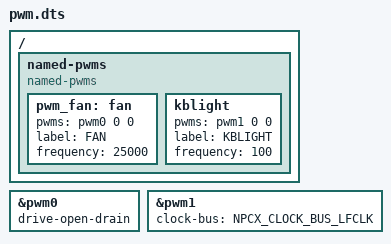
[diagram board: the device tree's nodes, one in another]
/* Copyright 2021 The Chromium OS Authors. All rights reserved.
 * Use of this source code is governed by a BSD-style license that can be
 * found in the LICENSE file.
 */

/ {
	named-pwms {
		compatible = "named-pwms";

		pwm_fan: fan {
			pwms = <&pwm0 0 0>;
			label = "FAN";
			frequency = <25000>;
		};
		kblight: kblight {
			pwms = <&pwm1 0 0>;
			label = "KBLIGHT";
			frequency = <100>;
		};
	};
};

/* Fan control */
&pwm0 {
	status = "okay";
	drive-open-drain;
};

/* Keyboard backlight */
&pwm1 {
	status = "okay";
	clock-bus = "NPCX_CLOCK_BUS_LFCLK";
};
